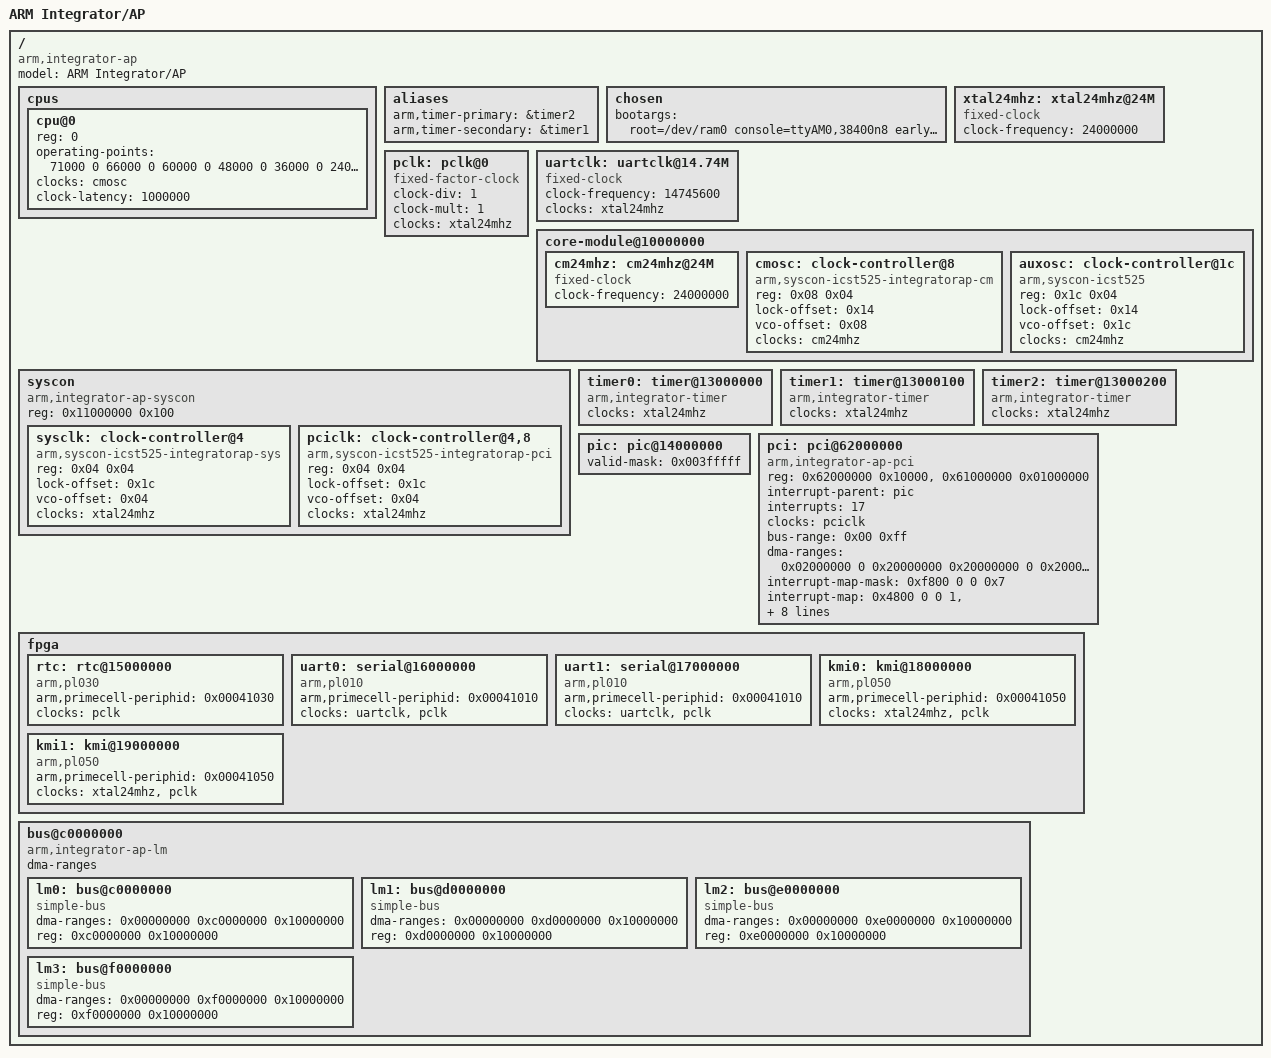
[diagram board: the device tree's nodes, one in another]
/dts-v1/;
#include "integrator.dtsi"
#include <dt-bindings/gpio/gpio.h>
#include <dt-bindings/input/input.h>
/ {
	model = "ARM Integrator/AP";
	compatible = "arm,integrator-ap";
	cpus {
		#address-cells = <1>;
		#size-cells = <0>;
		cpu@0 {
			device_type = "cpu";
			reg = <0>;
			operating-points = <71000  0
					    66000  0
					    60000  0
					    48000  0
					    36000  0
					    24000  0
					    12000  0>;
			clocks = <&cmosc>;
			clock-names = "cpu";
			clock-latency = <1000000>;  
		};
	};
	aliases {
		arm,timer-primary = &timer2;
		arm,timer-secondary = &timer1;
	};
	chosen {
		bootargs = "root=/dev/ram0 console=ttyAM0,38400n8 earlyprintk";
	};
	xtal24mhz: xtal24mhz@24M {
		#clock-cells = <0>;
		compatible = "fixed-clock";
		clock-frequency = <24000000>;
	};
	pclk: pclk@0 {
		#clock-cells = <0>;
		compatible = "fixed-factor-clock";
		clock-div = <1>;
		clock-mult = <1>;
		clocks = <&xtal24mhz>;
	};
	uartclk: uartclk@14.74M {
		#clock-cells = <0>;
		compatible = "fixed-clock";
		clock-frequency = <14745600>;
		clocks = <&xtal24mhz>;
	};
	core-module@10000000 {
		cm24mhz: cm24mhz@24M {
			#clock-cells = <0>;
			compatible = "fixed-clock";
			clock-frequency = <24000000>;
		};
		cmosc: clock-controller@8 {
			compatible = "arm,syscon-icst525-integratorap-cm";
			reg = <0x08 0x04>;
			#clock-cells = <0>;
			lock-offset = <0x14>;
			vco-offset = <0x08>;
			clocks = <&cm24mhz>;
		};
		auxosc: clock-controller@1c {
			compatible = "arm,syscon-icst525";
			reg = <0x1c 0x04>;
			#clock-cells = <0>;
			lock-offset = <0x14>;
			vco-offset = <0x1c>;
			clocks = <&cm24mhz>;
		};
	};
	syscon {
		compatible = "arm,integrator-ap-syscon", "syscon";
		reg = <0x11000000 0x100>;
		ranges = <0x0 0x11000000 0x100>;
		#size-cells = <1>;
		#address-cells = <1>;
		sysclk: clock-controller@4 {
			compatible = "arm,syscon-icst525-integratorap-sys";
			reg = <0x04 0x04>;
			#clock-cells = <0>;
			lock-offset = <0x1c>;
			vco-offset = <0x04>;
			clocks = <&xtal24mhz>;
		};
		pciclk: clock-controller@4,8 {
			compatible = "arm,syscon-icst525-integratorap-pci";
			reg = <0x04 0x04>;
			#clock-cells = <0>;
			lock-offset = <0x1c>;
			vco-offset = <0x04>;
			clocks = <&xtal24mhz>;
		};
	};
	timer0: timer@13000000 {
		compatible = "arm,integrator-timer";
		clocks = <&xtal24mhz>;
	};
	timer1: timer@13000100 {
		compatible = "arm,integrator-timer";
		clocks = <&xtal24mhz>;
	};
	timer2: timer@13000200 {
		compatible = "arm,integrator-timer";
		clocks = <&xtal24mhz>;
	};
	pic: pic@14000000 {
		valid-mask = <0x003fffff>;
	};
	pci: pci@62000000 {
		compatible = "arm,integrator-ap-pci", "v3,v360epc-pci";
		device_type = "pci";
		#interrupt-cells = <1>;
		#size-cells = <2>;
		#address-cells = <3>;
		reg = <0x62000000 0x10000>, <0x61000000 0x01000000>;
		interrupt-parent = <&pic>;
		interrupts = <17>;  
		clocks = <&pciclk>;
		bus-range = <0x00 0xff>;
		ranges = <0x01000000 0 0x0000000  
			0x60000000 0 0x00010000  
			0x02000000 0 0x40000000  
			0x40000000 0 0x10000000  
			0x42000000 0 0x50000000  
			0x50000000 0 0x10000000>;  
		dma-ranges = <0x02000000 0 0x20000000  
			0x20000000 0 0x20000000  
			0x02000000 0 0x80000000  
			0x80000000 0 0x40000000>;  
		interrupt-map-mask = <0xf800 0 0 0x7>;
		interrupt-map = <
		0x4800 0 0 1 &pic 13  
		0x4800 0 0 2 &pic 14  
		0x4800 0 0 3 &pic 15  
		0x4800 0 0 4 &pic 16  
		0x5000 0 0 1 &pic 14  
		0x5000 0 0 2 &pic 15  
		0x5000 0 0 3 &pic 16  
		0x5000 0 0 4 &pic 13  
		0x5800 0 0 1 &pic 15  
		0x5800 0 0 2 &pic 16  
		0x5800 0 0 3 &pic 13  
		0x5800 0 0 4 &pic 14  
		0x6000 0 0 1 &pic 16  
		0x6000 0 0 2 &pic 13  
		0x6000 0 0 3 &pic 14  
		0x6000 0 0 4 &pic 15  
		>;
	};
	fpga {
		rtc: rtc@15000000 {
			compatible = "arm,pl030", "arm,primecell";
			arm,primecell-periphid = <0x00041030>;
			clocks = <&pclk>;
			clock-names = "apb_pclk";
		};
		uart0: serial@16000000 {
			compatible = "arm,pl010", "arm,primecell";
			arm,primecell-periphid = <0x00041010>;
			clocks = <&uartclk>, <&pclk>;
			clock-names = "uartclk", "apb_pclk";
		};
		uart1: serial@17000000 {
			compatible = "arm,pl010", "arm,primecell";
			arm,primecell-periphid = <0x00041010>;
			clocks = <&uartclk>, <&pclk>;
			clock-names = "uartclk", "apb_pclk";
		};
		kmi0: kmi@18000000 {
			compatible = "arm,pl050", "arm,primecell";
			arm,primecell-periphid = <0x00041050>;
			clocks = <&xtal24mhz>, <&pclk>;
			clock-names = "KMIREFCLK", "apb_pclk";
		};
		kmi1: kmi@19000000 {
			compatible = "arm,pl050", "arm,primecell";
			arm,primecell-periphid = <0x00041050>;
			clocks = <&xtal24mhz>, <&pclk>;
			clock-names = "KMIREFCLK", "apb_pclk";
		};
	};
	bus@c0000000 {
		compatible = "arm,integrator-ap-lm";
		#address-cells = <1>;
		#size-cells = <1>;
		ranges = <0xc0000000 0xc0000000 0x40000000>;
		dma-ranges;
		lm0: bus@c0000000 {
			compatible = "simple-bus";
			ranges = <0x00000000 0xc0000000 0x10000000>;
			dma-ranges = <0x00000000 0xc0000000 0x10000000>;
			reg = <0xc0000000 0x10000000>;
			#address-cells = <1>;
			#size-cells = <1>;
		};
		lm1: bus@d0000000 {
			compatible = "simple-bus";
			ranges = <0x00000000 0xd0000000 0x10000000>;
			dma-ranges = <0x00000000 0xd0000000 0x10000000>;
			reg = <0xd0000000 0x10000000>;
			#address-cells = <1>;
			#size-cells = <1>;
		};
		lm2: bus@e0000000 {
			compatible = "simple-bus";
			ranges = <0x00000000 0xe0000000 0x10000000>;
			dma-ranges = <0x00000000 0xe0000000 0x10000000>;
			reg = <0xe0000000 0x10000000>;
			#address-cells = <1>;
			#size-cells = <1>;
		};
		lm3: bus@f0000000 {
			compatible = "simple-bus";
			ranges = <0x00000000 0xf0000000 0x10000000>;
			dma-ranges = <0x00000000 0xf0000000 0x10000000>;
			reg = <0xf0000000 0x10000000>;
			#address-cells = <1>;
			#size-cells = <1>;
		};
	};
};
